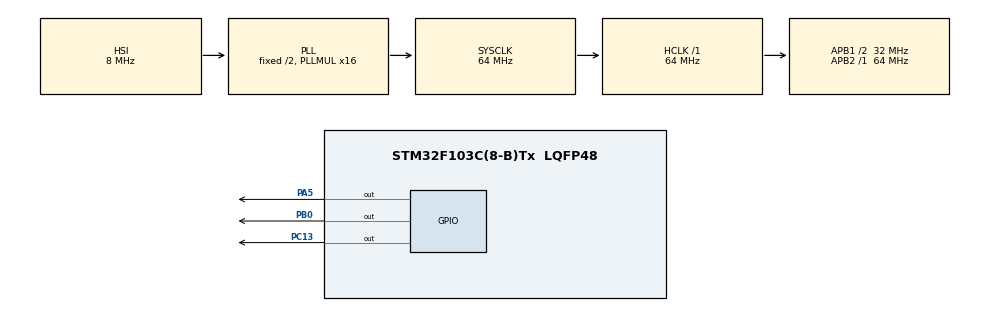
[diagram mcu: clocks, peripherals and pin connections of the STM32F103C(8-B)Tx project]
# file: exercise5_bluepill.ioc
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FREERTOS.Tasks01=defaultTask,0,128,StartDefaultTask,Default,NULL,Dynamic,NULL,NULL;StartGreenLedTa,-3,128,GreenLedTask,Default,NULL,Dynamic,NULL,NULL;StartRedLedTask,-3,128,RedLedTask,Default,NULL,Dynamic,NULL,NULL
Mcu.Family=STM32F1
Mcu.Name=STM32F103C(8-B)Tx
Mcu.Package=LQFP48
NVIC.PriorityGroup=NVIC_PRIORITYGROUP_4
PA13.Mode=Serial_Wire
PA13.Signal=SYS_JTMS-SWDIO
PA14.Mode=Serial_Wire
PA14.Signal=SYS_JTCK-SWCLK
PA5.Signal=GPIO_Output
PB0.Signal=GPIO_Output
PC13-TAMPER-RTC.Signal=GPIO_Output
ProjectManager.HeapSize=0x200
ProjectManager.StackSize=0x400
ProjectManager.TargetToolchain=STM32CubeIDE
RCC.AHBFreq_Value=64000000
RCC.APB1CLKDivider=RCC_HCLK_DIV2
RCC.APB1Freq_Value=32000000
RCC.APB1TimFreq_Value=64000000
RCC.APB2Freq_Value=64000000
RCC.APB2TimFreq_Value=64000000
RCC.HCLKFreq_Value=64000000
RCC.PLLMUL=RCC_PLL_MUL16
RCC.SYSCLKFreq_VALUE=64000000
RCC.SYSCLKSource=RCC_SYSCLKSOURCE_PLLCLK
RCC.USBFreq_Value=64000000
VP_FREERTOS_VS_CMSIS_V1.Mode=CMSIS_V1
board=custom

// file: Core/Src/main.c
/* USER CODE BEGIN Header */
/**
  ******************************************************************************
  * @file           : main.c
  * @brief          : Main program body
  ******************************************************************************
  * @attention
  *
  * Copyright (c) 2024 STMicroelectronics.
  * All rights reserved.
  *
  * This software is licensed under terms that can be found in the LICENSE file
  * in the root directory of this software component.
  * If no LICENSE file comes with this software, it is provided AS-IS.
  *
  ******************************************************************************
  */
/* USER CODE END Header */
#include "main.h"
#include "cmsis_os.h"

osThreadId defaultTaskHandle;
osThreadId StartGreenLedTaHandle;
osThreadId StartRedLedTaskHandle;
/* USER CODE BEGIN PV */
volatile uint8_t StartFlag = 1; // Inisialisasi StartFlag sebagai Up

/* USER CODE END PV */

void SystemClock_Config(void);
static void MX_GPIO_Init(void);
void StartDefaultTask(void const * argument);
void GreenLedTask(void const * argument);
void RedLedTask(void const * argument);

int main(void)
{

  /* MCU Configuration--------------------------------------------------------*/

  /* Reset of all peripherals, Initializes the Flash interface and the Systick. */
  HAL_Init();

  /* Configure the system clock */
  SystemClock_Config();

  /* Initialize all configured peripherals */
  MX_GPIO_Init();

  /* Create the thread(s) */
  /* definition and creation of defaultTask */
  osThreadDef(defaultTask, StartDefaultTask, osPriorityNormal, 0, 128);
  defaultTaskHandle = osThreadCreate(osThread(defaultTask), NULL);

  /* definition and creation of StartGreenLedTa */
  osThreadDef(StartGreenLedTa, GreenLedTask, osPriorityIdle, 0, 128);
  StartGreenLedTaHandle = osThreadCreate(osThread(StartGreenLedTa), NULL);

  /* definition and creation of StartRedLedTask */
  osThreadDef(StartRedLedTask, RedLedTask, osPriorityIdle, 0, 128);
  StartRedLedTaskHandle = osThreadCreate(osThread(StartRedLedTask), NULL);

  /* Start scheduler */
  osKernelStart();

  /* We should never get here as control is now taken by the scheduler */

  /* Infinite loop */
  while (1)
  {

  }
}

void SystemClock_Config(void)
{
  RCC_OscInitTypeDef RCC_OscInitStruct = {0};
  RCC_ClkInitTypeDef RCC_ClkInitStruct = {0};

  /** Initializes the RCC Oscillators according to the specified parameters
  * in the RCC_OscInitTypeDef structure.
  */
  RCC_OscInitStruct.OscillatorType = RCC_OSCILLATORTYPE_HSI;
  RCC_OscInitStruct.HSIState = RCC_HSI_ON;
  RCC_OscInitStruct.HSICalibrationValue = RCC_HSICALIBRATION_DEFAULT;
  RCC_OscInitStruct.PLL.PLLState = RCC_PLL_ON;
  RCC_OscInitStruct.PLL.PLLSource = RCC_PLLSOURCE_HSI_DIV2;
  RCC_OscInitStruct.PLL.PLLMUL = RCC_PLL_MUL16;
  if (HAL_RCC_OscConfig(&RCC_OscInitStruct) != HAL_OK)
  {
    Error_Handler();
  }

  /** Initializes the CPU, AHB and APB buses clocks
  */
  RCC_ClkInitStruct.ClockType = RCC_CLOCKTYPE_HCLK|RCC_CLOCKTYPE_SYSCLK
                              |RCC_CLOCKTYPE_PCLK1|RCC_CLOCKTYPE_PCLK2;
  RCC_ClkInitStruct.SYSCLKSource = RCC_SYSCLKSOURCE_PLLCLK;
  RCC_ClkInitStruct.AHBCLKDivider = RCC_SYSCLK_DIV1;
  RCC_ClkInitStruct.APB1CLKDivider = RCC_HCLK_DIV2;
  RCC_ClkInitStruct.APB2CLKDivider = RCC_HCLK_DIV1;

  if (HAL_RCC_ClockConfig(&RCC_ClkInitStruct, FLASH_LATENCY_2) != HAL_OK)
  {
    Error_Handler();
  }
}

static void MX_GPIO_Init(void)
{
  GPIO_InitTypeDef GPIO_InitStruct = {0};

  /* GPIO Ports Clock Enable */
  __HAL_RCC_GPIOC_CLK_ENABLE();
  __HAL_RCC_GPIOA_CLK_ENABLE();
  __HAL_RCC_GPIOB_CLK_ENABLE();

  /*Configure GPIO pin Output Level */
  HAL_GPIO_WritePin(GPIOC, GPIO_PIN_13, GPIO_PIN_RESET);

  /*Configure GPIO pin Output Level */
  HAL_GPIO_WritePin(GPIOA, GPIO_PIN_5, GPIO_PIN_RESET);

  /*Configure GPIO pin Output Level */
  HAL_GPIO_WritePin(GPIOB, GPIO_PIN_0, GPIO_PIN_RESET);

  /*Configure GPIO pin : PC13 */
  GPIO_InitStruct.Pin = GPIO_PIN_13;
  GPIO_InitStruct.Mode = GPIO_MODE_OUTPUT_PP;
  GPIO_InitStruct.Pull = GPIO_NOPULL;
  GPIO_InitStruct.Speed = GPIO_SPEED_FREQ_LOW;
  HAL_GPIO_Init(GPIOC, &GPIO_InitStruct);

  /*Configure GPIO pin : PA5 */
  GPIO_InitStruct.Pin = GPIO_PIN_5;
  GPIO_InitStruct.Mode = GPIO_MODE_OUTPUT_PP;
  GPIO_InitStruct.Pull = GPIO_NOPULL;
  GPIO_InitStruct.Speed = GPIO_SPEED_FREQ_LOW;
  HAL_GPIO_Init(GPIOA, &GPIO_InitStruct);

  /*Configure GPIO pin : PB0 */
  GPIO_InitStruct.Pin = GPIO_PIN_0;
  GPIO_InitStruct.Mode = GPIO_MODE_OUTPUT_PP;
  GPIO_InitStruct.Pull = GPIO_NOPULL;
  GPIO_InitStruct.Speed = GPIO_SPEED_FREQ_LOW;
  HAL_GPIO_Init(GPIOB, &GPIO_InitStruct);

}

/* USER CODE BEGIN 4 */
void Access_Shared_Data(void) {
    if (StartFlag == 1) { // Jika resource bebas diakses
        StartFlag = 0; // Tandai resource sedang diakses
    } else {
        HAL_GPIO_WritePin(GPIOC, GPIO_PIN_13, GPIO_PIN_SET); // Nyalakan Blue LED jika kontensi terjadi
        HAL_Delay(100); // Biarkan Blue LED menyala selama 0.1 detik
        HAL_GPIO_WritePin(GPIOC, GPIO_PIN_13, GPIO_PIN_RESET); // Matikan Blue LED
    }
    HAL_Delay(500); // Simulasi proses akses data selama 500 ms
    StartFlag = 1; // Reset StartFlag menjadi Up
}
/* USER CODE END 4 */

void StartDefaultTask(void const * argument)
{
  for(;;)
  {
    osDelay(1);
  }
}

void GreenLedTask(void const * argument)
{
  /* USER CODE BEGIN GreenLedTask */
  /* Infinite loop */
	for(;;)
	{
	    HAL_GPIO_WritePin(GPIOA, GPIO_PIN_5, GPIO_PIN_SET); // Nyalakan Green LED
	    Access_Shared_Data(); // Akses resource bersama
	    HAL_GPIO_WritePin(GPIOA, GPIO_PIN_5, GPIO_PIN_RESET); // Matikan Green LED
	    osDelay(2500);
	}
  /* USER CODE END GreenLedTask */
}

void RedLedTask(void const * argument)
{
  /* USER CODE BEGIN RedLedTask */
  /* Infinite loop */
	for(;;)
	{
	    HAL_GPIO_WritePin(GPIOB, GPIO_PIN_0, GPIO_PIN_SET); // Nyalakan Red LED
	    Access_Shared_Data(); // Akses resource bersama
	    HAL_GPIO_WritePin(GPIOB, GPIO_PIN_0, GPIO_PIN_RESET); // Matikan Red LED
	    osDelay(500);
	}
  /* USER CODE END RedLedTask */
}

void Error_Handler(void)
{
  __disable_irq();
  while (1)
  {
  }
}
